VERSION ""

NS_ :

BS_:

BU_: VCU AMK

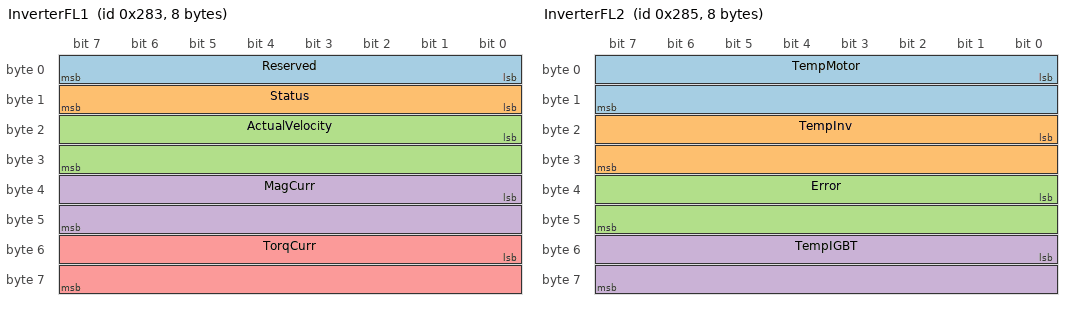
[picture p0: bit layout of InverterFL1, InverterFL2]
BO_ 643 InverterFL1: 8 AMK
 SG_ Reserved : 0|8@1+ (1,0) [0|0] ""  VCU
 SG_ Status : 8|8@1+ (1,0) [0|0] ""  VCU
 SG_ ActualVelocity : 16|16@1+ (1,0) [0|0] ""  VCU
 SG_ MagCurr : 32|16@1+ (1,0) [0|0] ""  VCU
 SG_ TorqCurr : 48|16@1+ (1,0) [0|0] ""  VCU

BO_ 645 InverterFL2: 8 AMK
 SG_ TempMotor : 0|16@1+ (1,0) [0|0] ""  VCU
 SG_ TempInv : 16|16@1+ (1,0) [0|0] ""  VCU
 SG_ Error : 32|16@1+ (1,0) [0|0] ""  VCU
 SG_ TempIGBT : 48|16@1+ (1,0) [0|0] ""  VCU

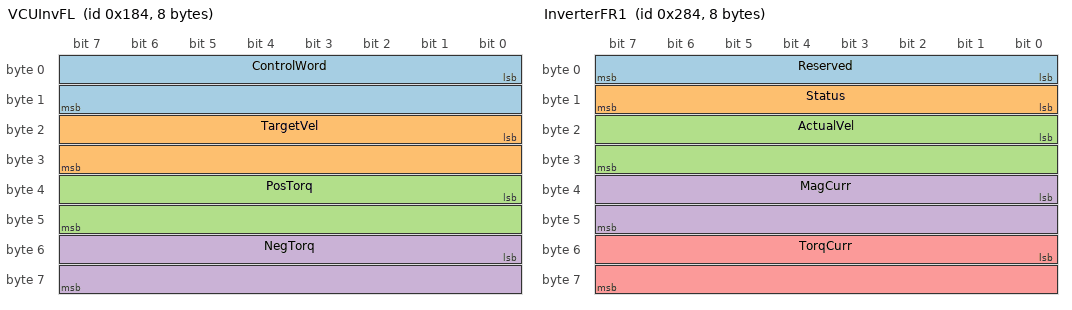
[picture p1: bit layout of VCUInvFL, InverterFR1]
BO_ 388 VCUInvFL: 8 VCU
 SG_ ControlWord : 0|16@1+ (1,0) [0|0] ""  AMK
 SG_ TargetVel : 16|16@1+ (1,0) [0|0] ""  AMK
 SG_ PosTorq : 32|16@1+ (1,0) [0|0] ""  AMK
 SG_ NegTorq : 48|16@1+ (1,0) [0|0] ""  AMK

BO_ 644 InverterFR1: 8 AMK
 SG_ Reserved : 0|8@1+ (1,0) [0|0] ""  VCU
 SG_ Status : 8|8@1+ (1,0) [0|0] ""  VCU
 SG_ ActualVel : 16|16@1+ (1,0) [0|0] ""  VCU
 SG_ MagCurr : 32|16@1+ (1,0) [0|0] ""  VCU
 SG_ TorqCurr : 48|16@1+ (1,0) [0|0] ""  VCU

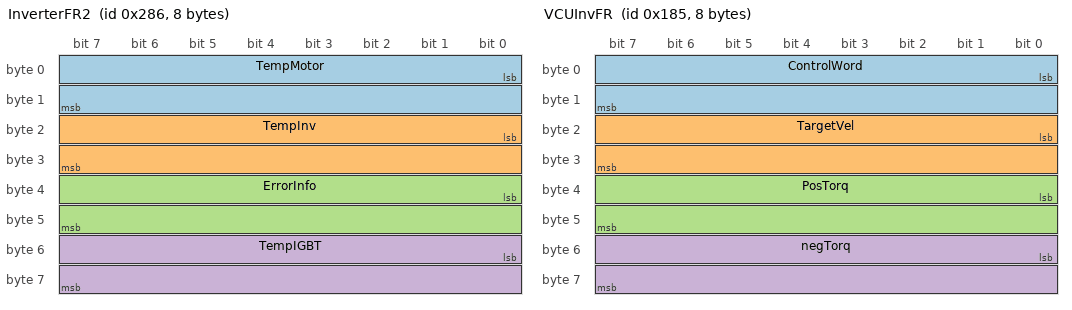
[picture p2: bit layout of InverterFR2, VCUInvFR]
BO_ 646 InverterFR2: 8 AMK
 SG_ TempMotor : 0|16@1+ (1,0) [0|0] ""  VCU
 SG_ TempInv : 16|16@1+ (1,0) [0|0] ""  VCU
 SG_ ErrorInfo : 32|16@1+ (1,0) [0|0] ""  VCU
 SG_ TempIGBT : 48|16@1+ (1,0) [0|0] ""  VCU

BO_ 389 VCUInvFR: 8 VCU
 SG_ ControlWord : 0|16@1+ (1,0) [0|0] ""  AMK
 SG_ TargetVel : 16|16@1+ (1,0) [0|0] ""  AMK
 SG_ PosTorq : 32|16@1+ (1,0) [0|0] ""  AMK
 SG_ negTorq : 48|16@1+ (1,0) [0|0] ""  AMK

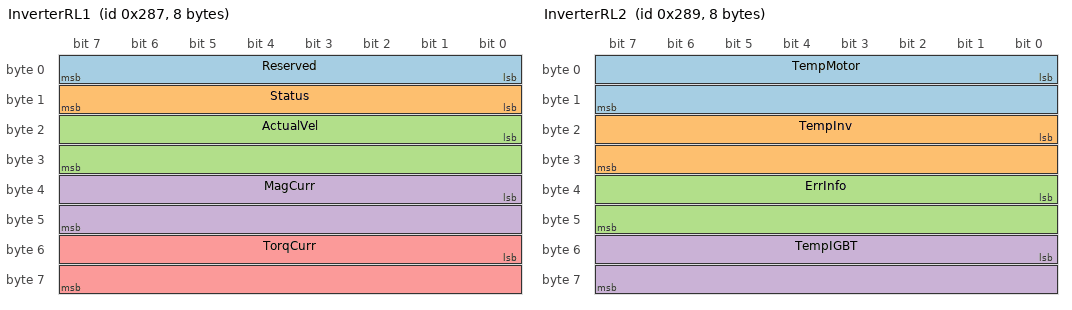
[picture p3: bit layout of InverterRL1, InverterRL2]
BO_ 647 InverterRL1: 8 AMK
 SG_ Reserved : 0|8@1+ (1,0) [0|0] ""  VCU
 SG_ Status : 8|8@1+ (1,0) [0|0] ""  VCU
 SG_ ActualVel : 16|16@1+ (1,0) [0|0] ""  VCU
 SG_ MagCurr : 32|16@1+ (1,0) [0|0] ""  VCU
 SG_ TorqCurr : 48|16@1+ (1,0) [0|0] ""  VCU

BO_ 649 InverterRL2: 8 AMK
 SG_ TempMotor : 0|16@1+ (1,0) [0|0] ""  VCU
 SG_ TempInv : 16|16@1+ (1,0) [0|0] ""  VCU
 SG_ ErrInfo : 32|16@1+ (1,0) [0|0] ""  VCU
 SG_ TempIGBT : 48|16@1+ (1,0) [0|0] ""  VCU

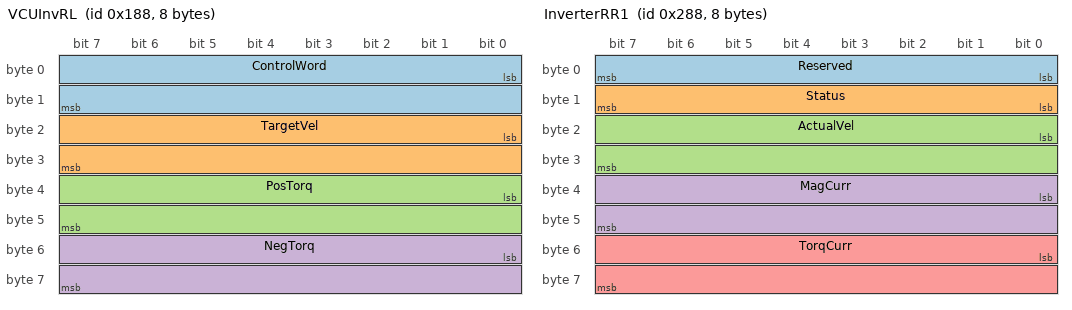
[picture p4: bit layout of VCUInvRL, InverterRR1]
BO_ 392 VCUInvRL: 8 VCU
 SG_ ControlWord : 0|16@1+ (1,0) [0|0] ""  AMK
 SG_ TargetVel : 16|16@1+ (1,0) [0|0] ""  AMK
 SG_ PosTorq : 32|16@1+ (1,0) [0|0] ""  AMK
 SG_ NegTorq : 48|16@1+ (1,0) [0|0] ""  AMK

BO_ 648 InverterRR1: 8 AMK
 SG_ Reserved : 0|8@1+ (1,0) [0|0] ""  VCU
 SG_ Status : 8|8@1+ (1,0) [0|0] ""  VCU
 SG_ ActualVel : 16|16@1+ (1,0) [0|0] ""  VCU
 SG_ MagCurr : 32|16@1+ (1,0) [0|0] ""  VCU
 SG_ TorqCurr : 48|16@1+ (1,0) [0|0] ""  VCU

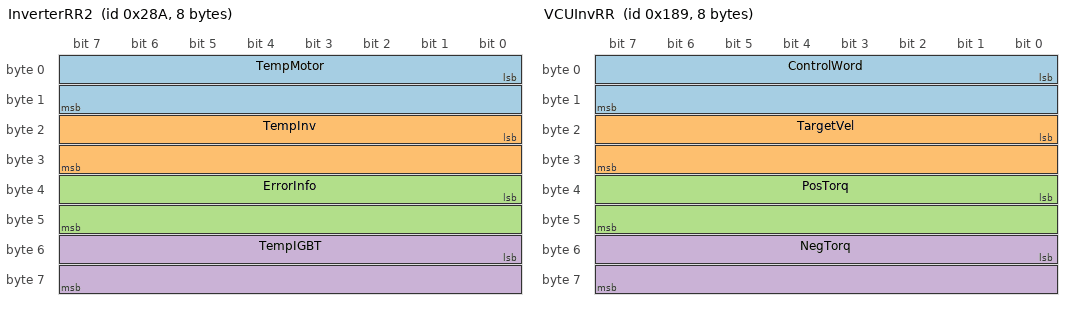
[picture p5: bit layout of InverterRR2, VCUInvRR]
BO_ 650 InverterRR2: 8 AMK
 SG_ TempMotor : 0|16@1+ (1,0) [0|0] ""  VCU
 SG_ TempInv : 16|16@1+ (1,0) [0|0] ""  VCU
 SG_ ErrorInfo : 32|16@1+ (1,0) [0|0] ""  VCU
 SG_ TempIGBT : 48|16@1+ (1,0) [0|0] ""  VCU

BO_ 393 VCUInvRR: 8 VCU
 SG_ ControlWord : 0|16@1+ (1,0) [0|0] ""  AMK
 SG_ TargetVel : 16|16@1+ (1,0) [0|0] ""  AMK
 SG_ PosTorq : 32|16@1+ (1,0) [0|0] ""  AMK
 SG_ NegTorq : 48|16@1+ (1,0) [0|0] ""  AMK
